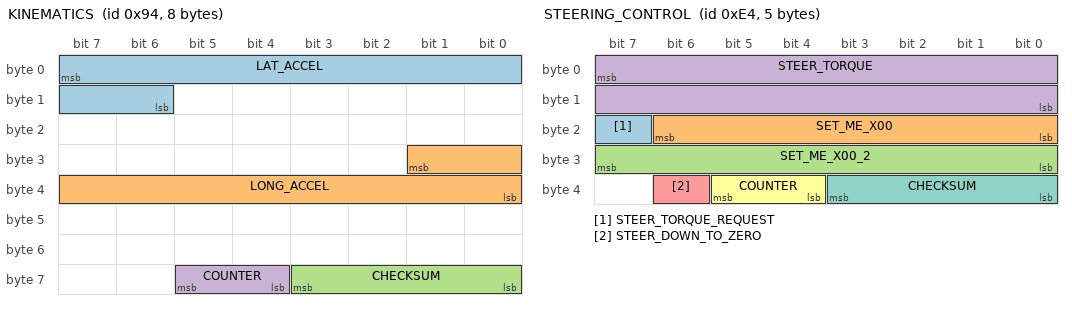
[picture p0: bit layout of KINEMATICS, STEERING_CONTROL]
BO_ 148 KINEMATICS: 8 XXX
 SG_ LAT_ACCEL : 7|10@0+ (-0.035,17.92) [-20|20] "m/s2" EON
 SG_ LONG_ACCEL : 25|10@0+ (-0.035,17.92) [-20|20] "m/s2" EON
 SG_ CHECKSUM : 59|4@0+ (1,0) [0|3] "" EON
 SG_ COUNTER : 61|2@0+ (1,0) [0|3] "" EON

BO_ 228 STEERING_CONTROL: 5 EON
 SG_ STEER_TORQUE_REQUEST : 23|1@0+ (1,0) [0|1] "" EPS
 SG_ SET_ME_X00 : 22|7@0+ (1,0) [0|127] "" EPS
 SG_ SET_ME_X00_2 : 31|8@0+ (1,0) [0|0] "" EPS
 SG_ STEER_TORQUE : 7|16@0- (1,0) [-4096|4096] "" EPS
 SG_ STEER_DOWN_TO_ZERO : 38|1@0+ (1,0) [0|1] "" EPS
 SG_ COUNTER : 37|2@0+ (1,0) [0|3] "" EPS
 SG_ CHECKSUM : 35|4@0+ (1,0) [0|15] "" EPS

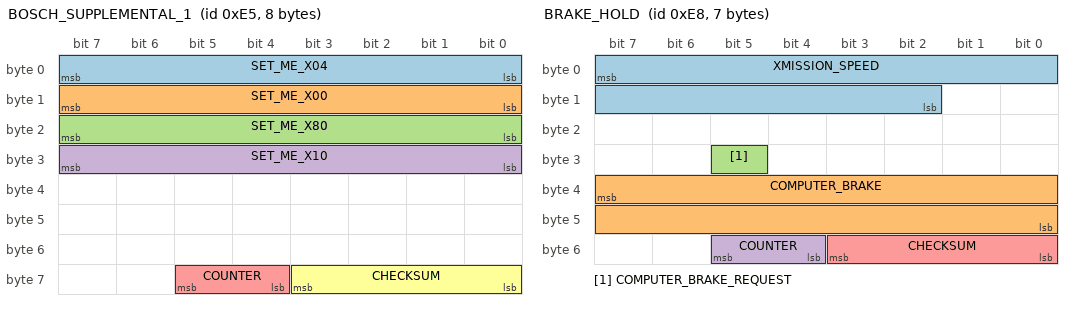
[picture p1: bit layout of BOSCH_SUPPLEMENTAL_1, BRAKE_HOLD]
BO_ 229 BOSCH_SUPPLEMENTAL_1: 8 XXX
 SG_ SET_ME_X04 : 0|8@1+ (1,0) [0|255] "" XXX
 SG_ SET_ME_X00 : 8|8@1+ (1,0) [0|255] "" XXX
 SG_ SET_ME_X80 : 16|8@1+ (1,0) [0|255] "" XXX
 SG_ SET_ME_X10 : 24|8@1+ (1,0) [0|255] "" XXX
 SG_ COUNTER : 61|2@0+ (1,0) [0|3] "" XXX
 SG_ CHECKSUM : 59|4@0+ (1,0) [0|15] "" XXX

BO_ 232 BRAKE_HOLD: 7 XXX
 SG_ XMISSION_SPEED : 7|14@0- (1,0) [1|0] "" XXX
 SG_ COMPUTER_BRAKE : 39|16@0+ (1,0) [0|0] "" XXX
 SG_ COMPUTER_BRAKE_REQUEST : 29|1@0+ (1,0) [0|0] "" XXX
 SG_ COUNTER : 53|2@0+ (1,0) [0|3] "" XXX
 SG_ CHECKSUM : 51|4@0+ (1,0) [0|15] "" XXX

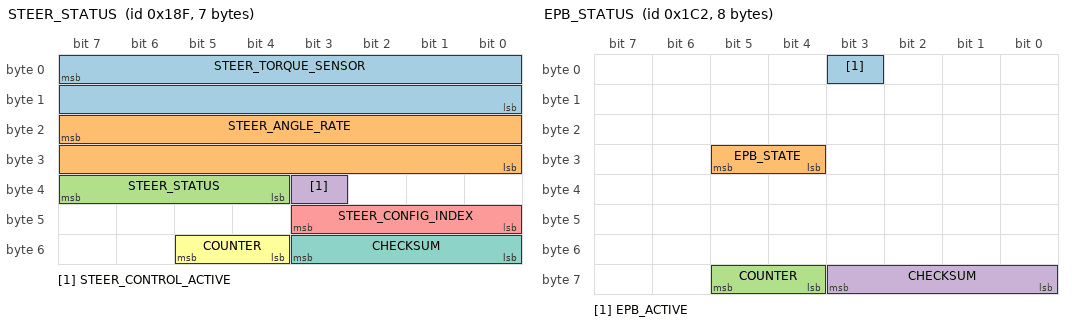
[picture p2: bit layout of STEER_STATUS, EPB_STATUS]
BO_ 399 STEER_STATUS: 7 EPS
 SG_ STEER_TORQUE_SENSOR : 7|16@0- (-1,0) [-31000|31000] "tbd" EON
 SG_ STEER_ANGLE_RATE : 23|16@0- (-0.1,0) [-31000|31000] "deg/s" EON
 SG_ STEER_STATUS : 39|4@0+ (1,0) [0|15] "" EON
 SG_ STEER_CONTROL_ACTIVE : 35|1@0+ (1,0) [0|1] "" EON
 SG_ STEER_CONFIG_INDEX : 43|4@0+ (1,0) [0|15] "" EON
 SG_ COUNTER : 53|2@0+ (1,0) [0|3] "" EON
 SG_ CHECKSUM : 51|4@0+ (1,0) [0|15] "" EON

BO_ 450 EPB_STATUS: 8 EPB
 SG_ EPB_ACTIVE : 3|1@0+ (1,0) [0|1] "" EON
 SG_ EPB_STATE : 29|2@0+ (1,0) [0|3] "" EON
 SG_ COUNTER : 61|2@0+ (1,0) [0|3] "" XXX
 SG_ CHECKSUM : 59|4@0+ (1,0) [0|15] "" XXX

CM_ SG_ 450 EPB_STATE "3: On, 2: Disengaging, 1: Engaging, 0: Off";

VAL_ 399 STEER_STATUS 6 "tmp_fault" 5 "fault_1" 4 "no_torque_alert_2" 3 "low_speed_lockout" 2 "no_torque_alert_1" 0 "normal";
VAL_ 422 CRUISE_BUTTONS 7 "tbd" 6 "tbd" 5 "tbd" 4 "accel_res" 3 "decel_set" 2 "cancel" 1 "main" 0 "none" ;
VAL_ 422 LIGHTS_SETTING 3 "high_beam" 2 "low_beam" 1 "position" 0 "no_lights" ;
VAL_ 422 CRUISE_SETTING 3 "distance_adj" 2 "tbd" 1 "lkas_button" 0 "none" ;
